# f29h85x_c29_selftest_regs register map
Vendor: Texas Instruments
Peripheral module from a debugger description file (folder C29).
Registers are 32-bit, read-write, no defined reset value unless marked. A register's access mark holds for its fields unless they carry their own. Offsets are as the file gives them; lines under a group give offsets from that group; [hi:lo] are bit positions; {n}, {i} and the like mark numbered series; 'fields as' and 'values as' point back to an identical list; <NAME> marks a mode.

## C29_SELFTEST_REGS — C29 SELFTEST Registers
{0x0+4i} SELFTEST_DIAG_DATA{i} (i=0..2) — Diagnostics data register {i}
  [31:0] SELFTEST_DIAG_DATA{i} — Self test Diagnostics data {i}
0x20 SELFTEST_DIAG_ECC — Diagnostics ECC
  [7:0] SELFTEST_DIAG_ECC — Self test Diagnostics ECC
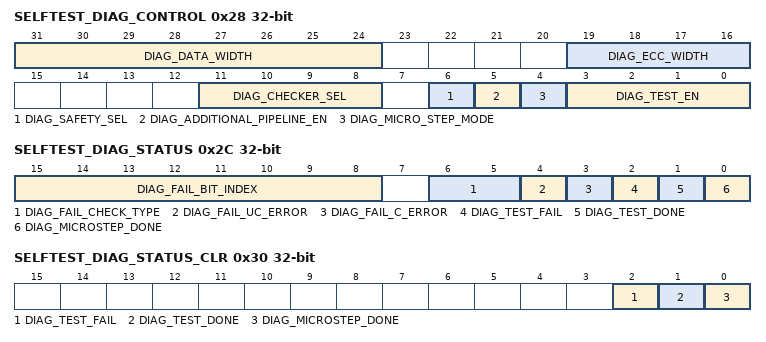
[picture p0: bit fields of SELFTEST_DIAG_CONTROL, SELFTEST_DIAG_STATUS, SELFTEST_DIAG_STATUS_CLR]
0x28 SELFTEST_DIAG_CONTROL — Diagnostic test enable
  [31:24] DIAG_DATA_WIDTH — Diagnostic Data width
  [19:16] DIAG_ECC_WIDTH — Diagnostic ECC width
  [11:8] DIAG_CHECKER_SEL — ECC checker selection
  [6] DIAG_SAFETY_SEL — Diagnostic safetly selection
  [5] DIAG_ADDITIONAL_PIPELINE_EN — Additional pipeline enable
  [4] DIAG_MICRO_STEP_MODE — Diagnostic micro step mode
  [3:0] DIAG_TEST_EN — Diagnostic test enable
0x2C SELFTEST_DIAG_STATUS ro — Diagnostic status register
  [15:8] DIAG_FAIL_BIT_INDEX — Error bit position
  [6:5] DIAG_FAIL_CHECK_TYPE — Failed diagnostic check type
  [4] DIAG_FAIL_UC_ERROR — Diagnostic uncorrectable error
  [3] DIAG_FAIL_C_ERROR — Diagnostic correctable error
  [2] DIAG_TEST_FAIL — Test failed
  [1] DIAG_TEST_DONE — Done self test
  [0] DIAG_MICROSTEP_DONE — Done Micro step
0x30 SELFTEST_DIAG_STATUS_CLR — Diagnostic status clear register
  [2] DIAG_TEST_FAIL — Clear test failed status flags
  [1] DIAG_TEST_DONE — Clear selftest done status flag
  [0] DIAG_MICROSTEP_DONE — Clear micro step done status flag
